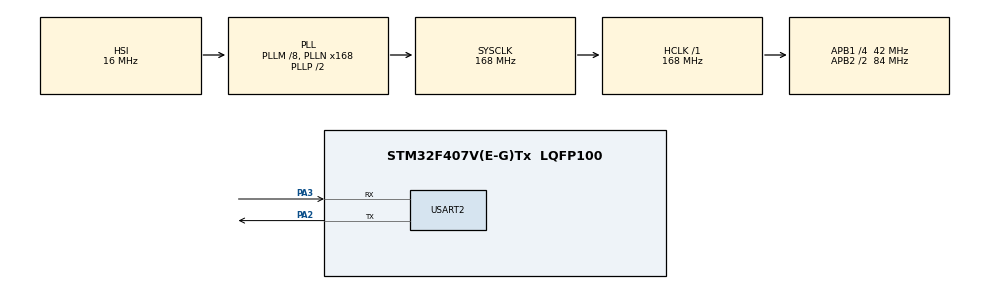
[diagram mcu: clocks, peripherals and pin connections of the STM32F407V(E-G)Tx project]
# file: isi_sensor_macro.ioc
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ADC1.Channel-0\#ChannelRegularConversion=ADC_CHANNEL_TEMPSENSOR
ADC1.ClockPrescaler=ADC_CLOCK_SYNC_PCLK_DIV4
ADC1.NbrOfConversionFlag=1
ADC1.Rank-0\#ChannelRegularConversion=1
ADC1.SamplingTime-0\#ChannelRegularConversion=ADC_SAMPLETIME_480CYCLES
ADC1.master=1
Dma.ADC1.0.Direction=DMA_PERIPH_TO_MEMORY
Dma.ADC1.0.FIFOMode=DMA_FIFOMODE_DISABLE
Dma.ADC1.0.Instance=DMA2_Stream0
Dma.ADC1.0.MemDataAlignment=DMA_MDATAALIGN_HALFWORD
Dma.ADC1.0.MemInc=DMA_MINC_ENABLE
Dma.ADC1.0.Mode=DMA_NORMAL
Dma.ADC1.0.PeriphDataAlignment=DMA_PDATAALIGN_HALFWORD
Dma.ADC1.0.PeriphInc=DMA_PINC_DISABLE
Dma.ADC1.0.Priority=DMA_PRIORITY_LOW
Dma.Request0=ADC1
Mcu.Family=STM32F4
Mcu.Name=STM32F407V(E-G)Tx
Mcu.Package=LQFP100
NVIC.ADC_IRQn=true\:0\:0\:false\:false\:true\:true\:true\:true
NVIC.DMA2_Stream0_IRQn=true\:0\:0\:false\:false\:true\:false\:true\:true
NVIC.PriorityGroup=NVIC_PRIORITYGROUP_4
PA13.Mode=Serial_Wire
PA13.Signal=SYS_JTMS-SWDIO
PA14.Mode=Serial_Wire
PA14.Signal=SYS_JTCK-SWCLK
PA2.Mode=Asynchronous
PA2.Signal=USART2_TX
PA3.Mode=Asynchronous
PA3.Signal=USART2_RX
ProjectManager.HeapSize=0x200
ProjectManager.StackSize=0x400
ProjectManager.TargetToolchain=STM32CubeIDE
RCC.48MHZClocksFreq_Value=84000000
RCC.AHBFreq_Value=168000000
RCC.APB1CLKDivider=RCC_HCLK_DIV4
RCC.APB1Freq_Value=42000000
RCC.APB1TimFreq_Value=84000000
RCC.APB2CLKDivider=RCC_HCLK_DIV2
RCC.APB2Freq_Value=84000000
RCC.APB2TimFreq_Value=168000000
RCC.CortexFreq_Value=168000000
RCC.HCLKFreq_Value=168000000
RCC.HSE_VALUE=25000000
RCC.HSI_VALUE=16000000
RCC.LSE_VALUE=32768
RCC.PLLM=8
RCC.PLLN=168
RCC.SYSCLKFreq_VALUE=168000000
RCC.SYSCLKSource=RCC_SYSCLKSOURCE_PLLCLK
RCC.VCOOutputFreq_Value=336000000
USART2.VirtualMode=VM_ASYNC
VP_ADC1_TempSens_Input.Mode=IN-TempSens
board=custom

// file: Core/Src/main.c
/* USER CODE BEGIN Header */
/**
  ******************************************************************************
  * @file           : main.c
  * @brief          : Main program body
  ******************************************************************************
  * @attention
  *
  * Copyright (c) 2025 STMicroelectronics.
  * All rights reserved.
  *
  * This software is licensed under terms that can be found in the LICENSE file
  * in the root directory of this software component.
  * If no LICENSE file comes with this software, it is provided AS-IS.
  *
  ******************************************************************************
  */
/* USER CODE END Header */
#include "main.h"
#include <stdio.h>
#include "adc_methods.h"

ADC_HandleTypeDef hadc1;
DMA_HandleTypeDef hdma_adc1;

UART_HandleTypeDef huart2;

/* USER CODE BEGIN PV */
DMA_HandleTypeDef hdma_adc1;
uint32_t last_measurement_time = 0;   // zaman kontrolü
#define MEASUREMENT_INTERVAL 1000     // 1 saniye

/* USER CODE END PV */

void SystemClock_Config(void);
static void MX_GPIO_Init(void);
static void MX_DMA_Init(void);
static void MX_ADC1_Init(void);
static void MX_USART2_UART_Init(void);

int main(void)
{

  /* MCU Configuration--------------------------------------------------------*/

  /* Reset of all peripherals, Initializes the Flash interface and the Systick. */
  HAL_Init();

  /* Configure the system clock */
  SystemClock_Config();

  /* Initialize all configured peripherals */
  MX_GPIO_Init();
  MX_DMA_Init();
  MX_ADC1_Init();
  MX_USART2_UART_Init();
  /* USER CODE BEGIN 2 */
  // 🟢 DMA'yı başlat (SADECE BİR KEZ)
  printf("🚀 ADC baslatiyor...\r\n");

      printf("🚀 STM32F4 Sıcaklık Sensörü Başlatılıyor...\r\n");
      printf("🔧 System Clock: %lu Hz\r\n", HAL_RCC_GetSysClockFreq());
      printf("🔧 ADC Clock: %lu Hz\r\n", HAL_RCC_GetPCLK2Freq() / 8);

      // Sıcaklık sensörü için ek bekleme
      HAL_Delay(100);

      // İlk test ölçümü
      printf("\r\n--- İLK TEST ÖLÇÜMÜ ---\r\n");
      Read_Temperature(&hadc1);

      printf("\r\n--- NORMAL ÖLÇÜMLER BAŞLIYOR ---\r\n");

  /* USER CODE END 2 */

  /* Infinite loop */
  while (1)
  {

    /* USER CODE BEGIN 3 */
	    printf("\r\n--- Yeni Olcum ---\r\n");

	    //Read_Temperature_Polling(&hadc1);
	    Read_Temperature(&hadc1);

	    HAL_Delay(2000);

	    //HAL_ADC_Start(&hadc1);
	    //if (HAL_ADC_PollForConversion(&hadc1, 1000) == HAL_OK)
	    //{
	        //uint32_t raw_value = HAL_ADC_GetValue(&hadc1);
	        //float voltage = (raw_value * 3.3f) / 4095.0f;

	        // 🧮 Sıcaklık hesapla
	        //float temperature = Convert_ADC_to_Temperature(raw_value);
	        //printf("ADC: %lu | Voltage: %.3f V | Temp: %.2f °C\r\n", // @suppress("Float formatting support")
	               //raw_value, voltage, temperature);

	    //}
	    //else
	    //{
	        //printf("❌ Conversion Timeout!\r\n");
	    //}

	    //HAL_ADC_Stop(&hadc1);
	    //HAL_Delay(2000);
    /* USER CODE BEGIN 3 */
  }
  /* USER CODE END 3 */
}

void SystemClock_Config(void)
{
  RCC_OscInitTypeDef RCC_OscInitStruct = {0};
  RCC_ClkInitTypeDef RCC_ClkInitStruct = {0};

  /** Configure the main internal regulator output voltage
  */
  __HAL_RCC_PWR_CLK_ENABLE();
  __HAL_PWR_VOLTAGESCALING_CONFIG(PWR_REGULATOR_VOLTAGE_SCALE1);

  /** Initializes the RCC Oscillators according to the specified parameters
  * in the RCC_OscInitTypeDef structure.
  */
  RCC_OscInitStruct.OscillatorType = RCC_OSCILLATORTYPE_HSI;
  RCC_OscInitStruct.HSIState = RCC_HSI_ON;
  RCC_OscInitStruct.HSICalibrationValue = RCC_HSICALIBRATION_DEFAULT;
  RCC_OscInitStruct.PLL.PLLState = RCC_PLL_ON;
  RCC_OscInitStruct.PLL.PLLSource = RCC_PLLSOURCE_HSI;
  RCC_OscInitStruct.PLL.PLLM = 8;
  RCC_OscInitStruct.PLL.PLLN = 168;
  RCC_OscInitStruct.PLL.PLLP = RCC_PLLP_DIV2;
  RCC_OscInitStruct.PLL.PLLQ = 4;
  if (HAL_RCC_OscConfig(&RCC_OscInitStruct) != HAL_OK)
  {
    Error_Handler();
  }

  /** Initializes the CPU, AHB and APB buses clocks
  */
  RCC_ClkInitStruct.ClockType = RCC_CLOCKTYPE_HCLK|RCC_CLOCKTYPE_SYSCLK
                              |RCC_CLOCKTYPE_PCLK1|RCC_CLOCKTYPE_PCLK2;
  RCC_ClkInitStruct.SYSCLKSource = RCC_SYSCLKSOURCE_PLLCLK;
  RCC_ClkInitStruct.AHBCLKDivider = RCC_SYSCLK_DIV1;
  RCC_ClkInitStruct.APB1CLKDivider = RCC_HCLK_DIV4;
  RCC_ClkInitStruct.APB2CLKDivider = RCC_HCLK_DIV2;

  if (HAL_RCC_ClockConfig(&RCC_ClkInitStruct, FLASH_LATENCY_5) != HAL_OK)
  {
    Error_Handler();
  }
}

static void MX_ADC1_Init(void)
{

  ADC_ChannelConfTypeDef sConfig = {0};

  /** Configure the global features of the ADC (Clock, Resolution, Data Alignment and number of conversion)
  */
  hadc1.Instance = ADC1;
  hadc1.Init.ClockPrescaler = ADC_CLOCK_SYNC_PCLK_DIV4;
  hadc1.Init.Resolution = ADC_RESOLUTION_12B;
  hadc1.Init.ScanConvMode = DISABLE;
  hadc1.Init.ContinuousConvMode = DISABLE;
  hadc1.Init.DiscontinuousConvMode = DISABLE;
  hadc1.Init.ExternalTrigConvEdge = ADC_EXTERNALTRIGCONVEDGE_NONE;
  hadc1.Init.ExternalTrigConv = ADC_SOFTWARE_START;
  hadc1.Init.DataAlign = ADC_DATAALIGN_RIGHT;
  hadc1.Init.NbrOfConversion = 1;
  hadc1.Init.DMAContinuousRequests = DISABLE;
  hadc1.Init.EOCSelection = ADC_EOC_SINGLE_CONV;
  if (HAL_ADC_Init(&hadc1) != HAL_OK)
  {
    Error_Handler();
  }

  /** Configure for the selected ADC regular channel its corresponding rank in the sequencer and its sample time.
  */
  sConfig.Channel = ADC_CHANNEL_TEMPSENSOR;
  sConfig.Rank = 1;
  sConfig.SamplingTime = ADC_SAMPLETIME_480CYCLES;
  if (HAL_ADC_ConfigChannel(&hadc1, &sConfig) != HAL_OK)
  {
    Error_Handler();
  }

}

static void MX_USART2_UART_Init(void)
{

  huart2.Instance = USART2;
  huart2.Init.BaudRate = 115200;
  huart2.Init.WordLength = UART_WORDLENGTH_8B;
  huart2.Init.StopBits = UART_STOPBITS_1;
  huart2.Init.Parity = UART_PARITY_NONE;
  huart2.Init.Mode = UART_MODE_TX_RX;
  huart2.Init.HwFlowCtl = UART_HWCONTROL_NONE;
  huart2.Init.OverSampling = UART_OVERSAMPLING_16;
  HAL_UART_Init(&huart2);   //yenii.
  if (HAL_UART_Init(&huart2) != HAL_OK)
  {
    Error_Handler();
  }

}

static void MX_DMA_Init(void)
{

  /* DMA controller clock enable */
  __HAL_RCC_DMA2_CLK_ENABLE();

  /* DMA interrupt init */
  /* DMA2_Stream0_IRQn interrupt configuration */
  HAL_NVIC_SetPriority(DMA2_Stream0_IRQn, 0, 0);
  HAL_NVIC_EnableIRQ(DMA2_Stream0_IRQn);

}

static void MX_GPIO_Init(void)
{

  /* GPIO Ports Clock Enable */
  __HAL_RCC_GPIOA_CLK_ENABLE();

}

/* USER CODE BEGIN 4 */

// DMA Transfer Complete callback
//void HAL_ADC_ConvCpltCallback(ADC_HandleTypeDef* hadc)
//{
    //if (hadc->Instance == ADC1)
    //{
        //printf("🔔 DMA Callback cagirildi! ADC: %lu\r\n", adc_value);
        //temperature = Convert_ADC_to_Temperature(adc_value);
    //}
//}

// DMA Error callback
//void HAL_ADC_ErrorCallback(ADC_HandleTypeDef *hadc)
//{
    //printf("❌ DMA HATA! Status: %lu\r\n", HAL_ADC_GetError(hadc));
//}

//int _write(int file, char *ptr, int len)
//{
    //HAL_UART_Transmit(&huart2, (uint8_t *)ptr, len, HAL_MAX_DELAY); sonn..
    //return len; sonn..

    //for (int i = 0; i < len; i++)
    //{
        //ITM_SendChar(*ptr++); // 🟢 SWV ITM Kanalına gönder
    //}
    //return len;
//}

/* USER CODE END 4 */

void Error_Handler(void)
{
  __disable_irq();
  while (1)
  {
  }
}
